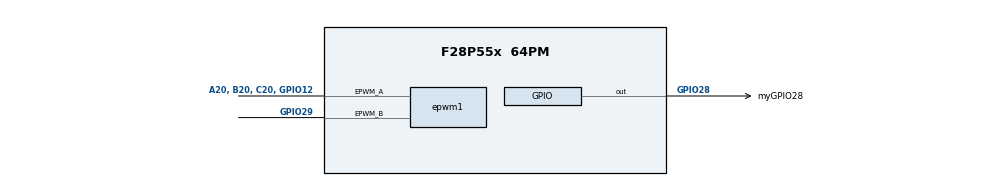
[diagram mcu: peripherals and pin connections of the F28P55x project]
/**
 * @cliArgs --device "F28P55x" --part "F28P55x_64PM" --package "64PM" --context "system" --product "C2000WARE@5.05.00.00"
 * @versions {"tool":"1.25.0+4268"}
 */

/**
 * Import the modules used in this configuration.
 */
const adc              = scripting.addModule("/driverlib/adc.js", {}, false);
const adc1             = adc.addInstance();
const adc2             = adc.addInstance();
const analog           = scripting.addModule("/driverlib/analog.js", {}, false);
const analog1          = analog.addInstance();
const asysctl          = scripting.addModule("/driverlib/asysctl.js");
const cputimer         = scripting.addModule("/driverlib/cputimer.js", {}, false);
const cputimer1        = cputimer.addInstance();
const dac              = scripting.addModule("/driverlib/dac.js", {}, false);
const dac1             = dac.addInstance();
const dma              = scripting.addModule("/driverlib/dma.js", {}, false);
const dma1             = dma.addInstance();
const epwm             = scripting.addModule("/driverlib/epwm.js", {}, false);
const epwm1            = epwm.addInstance();
const gpio             = scripting.addModule("/driverlib/gpio.js", {}, false);
const gpio1            = gpio.addInstance();
const inputxbar_input  = scripting.addModule("/driverlib/inputxbar_input.js", {}, false);
const inputxbar_input1 = inputxbar_input.addInstance();
const FFT              = scripting.addModule("/libraries/dsp/FPU/FFT/FFT.js", {}, false);
const FFT1             = FFT.addInstance();
const FPUfastRTS       = scripting.addModule("/libraries/math/FPUfastRTS/FPUfastRTS.js", {}, false);
const FPUfastRTS1      = FPUfastRTS.addInstance();

/**
 * Write custom configuration values to the imported modules.
 */
adc1.$name                    = "myADC0";
adc1.adcClockPrescaler        = "ADC_CLK_DIV_2_0";
adc1.interruptPulseMode       = "ADC_PULSE_END_OF_CONV";
adc1.enabledInts              = ["ADC_INT_NUMBER1"];
adc1.enableInterrupt1         = true;
adc1.registerInterrupts       = ["1"];
adc1.soc0Channel              = "ADC_CH_ADCIN6";
adc1.soc0Trigger              = "ADC_TRIGGER_EPWM7_SOCA";
adc1.enabledSOCs              = ["ADC_SOC_NUMBER0","ADC_SOC_NUMBER1","ADC_SOC_NUMBER10","ADC_SOC_NUMBER11","ADC_SOC_NUMBER12","ADC_SOC_NUMBER13","ADC_SOC_NUMBER14","ADC_SOC_NUMBER2","ADC_SOC_NUMBER3","ADC_SOC_NUMBER4","ADC_SOC_NUMBER5","ADC_SOC_NUMBER6","ADC_SOC_NUMBER7","ADC_SOC_NUMBER8","ADC_SOC_NUMBER9"];
adc1.soc0SampleWindow         = 20;
adc1.soc1Channel              = "ADC_CH_ADCIN2";
adc1.soc1Trigger              = "ADC_TRIGGER_EPWM7_SOCA";
adc1.soc1SampleWindow         = 20;
adc1.soc2Channel              = "ADC_CH_ADCIN11";
adc1.soc2Trigger              = "ADC_TRIGGER_EPWM7_SOCA";
adc1.soc2SampleWindow         = 20;
adc1.soc3Channel              = "ADC_CH_ADCIN12";
adc1.soc3Trigger              = "ADC_TRIGGER_EPWM7_SOCA";
adc1.soc3SampleWindow         = 20;
adc1.soc4Channel              = "ADC_CH_ADCIN4";
adc1.soc4Trigger              = "ADC_TRIGGER_EPWM7_SOCA";
adc1.soc4SampleWindow         = 20;
adc1.soc5Channel              = "ADC_CH_ADCIN15";
adc1.soc5Trigger              = "ADC_TRIGGER_EPWM7_SOCA";
adc1.soc5SampleWindow         = 20;
adc1.soc6Channel              = "ADC_CH_ADCIN5";
adc1.soc6Trigger              = "ADC_TRIGGER_EPWM7_SOCA";
adc1.soc6SampleWindow         = 20;
adc1.soc7Channel              = "ADC_CH_ADCIN7";
adc1.soc7Trigger              = "ADC_TRIGGER_EPWM7_SOCA";
adc1.soc7SampleWindow         = 20;
adc1.soc8Channel              = "ADC_CH_ADCIN9";
adc1.soc8Trigger              = "ADC_TRIGGER_EPWM7_SOCA";
adc1.soc8SampleWindow         = 20;
adc1.soc9Channel              = "ADC_CH_ADCIN3";
adc1.soc9Trigger              = "ADC_TRIGGER_EPWM7_SOCA";
adc1.soc9SampleWindow         = 20;
adc1.soc10Channel             = "ADC_CH_ADCIN14";
adc1.soc10Trigger             = "ADC_TRIGGER_EPWM7_SOCA";
adc1.soc10SampleWindow        = 20;
adc1.soc11Channel             = "ADC_CH_ADCIN1";
adc1.soc11Trigger             = "ADC_TRIGGER_EPWM7_SOCA";
adc1.soc11SampleWindow        = 20;
adc1.soc12Channel             = "ADC_CH_ADCIN8";
adc1.soc12Trigger             = "ADC_TRIGGER_EPWM7_SOCA";
adc1.soc12SampleWindow        = 20;
adc1.soc13Channel             = "ADC_CH_ADCIN24";
adc1.soc13Trigger             = "ADC_TRIGGER_EPWM7_SOCA";
adc1.soc13SampleWindow        = 20;
adc1.soc14Channel             = "ADC_CH_ADCIN25";
adc1.soc14Trigger             = "ADC_TRIGGER_EPWM7_SOCA";
adc1.soc14SampleWindow        = 20;
adc1.adcInt1.enableInterrupt  = true;
adc1.adcInt1.interruptHandler = "adcA1ISR";

adc2.$name             = "myADC1";
adc2.adcBase           = "ADCE_BASE";
adc2.adcClockPrescaler = "ADC_CLK_DIV_2_0";
adc2.enabledSOCs       = ["ADC_SOC_NUMBER0","ADC_SOC_NUMBER1","ADC_SOC_NUMBER2"];
adc2.soc0Channel       = "ADC_CH_ADCIN1";
adc2.soc0Trigger       = "ADC_TRIGGER_EPWM7_SOCA";
adc2.soc0SampleWindow  = 20;
adc2.soc1Channel       = "ADC_CH_ADCIN12";
adc2.soc1Trigger       = "ADC_TRIGGER_EPWM7_SOCA";
adc2.soc1SampleWindow  = 20;
adc2.soc2Channel       = "ADC_CH_ADCIN2";
adc2.soc2Trigger       = "ADC_TRIGGER_EPWM7_SOCA";
adc2.soc2SampleWindow  = 20;

asysctl.analogReference        = "INTERNAL";
asysctl.analogReferenceVoltage = "1P65";

cputimer1.$name                     = "myCPUTIMER0";
cputimer1.timerPeriod               = 23437;
cputimer1.enableInterrupt           = true;
cputimer1.registerInterrupts        = true;
cputimer1.startTimer                = true;
cputimer1.timerInt.interruptHandler = "cpuTimer0ISR";
cputimer1.timerInt.enableInterrupt  = true;

dac1.$name        = "myDAC0";
dac1.gainMode     = "DAC_GAIN_TWO";
dac1.shadowValue  = 2048;
dac1.enableOutput = true;

analog1.$name            = "myANALOGPinMux0";
adc1.analog              = analog1;
analog1.useCase          = "CUSTOM";
dac1.analog              = analog1;
analog1.useInterfacePins = ["A0, B15, C15, DACA_OUT","A1, B7, D11, CMP1_DACL","A11, B10, C0, PGA2_OUT","A12, C1, E11, PGA3_INP","A14, B14, C4, PGA1_OUT","A15, B9, C7, PGA1_INM","A2, B6, C9, PGA1_INP, GPIO224","A24, D0, E0, GPIO11","A25, D3, E3, GPIO17","A3, B3, PGA2_INP, C5, GPIO242","A4, B8, C14","A5, B12, C2, PGA2_INM","A6, D14, E14, GPIO228","A7, B30, C3, D12, E30, PGA3_INM","A8, B0, C11, PGA3_OUT","A9, B4, C8, GPIO227, GPIO236","B2, C6, E12, GPIO226","B24, D1, E1, GPIO33","C24, D2, E2, GPIO16"];
adc2.analog              = analog1;

dma1.$name            = "myDMA0";
dma1.enableTriggers   = true;
dma1.triggerSource    = "DMA_TRIGGER_ADCA1";
dma1.transferSize     = 1028;
dma1.emulationMode    = "DMA_EMULATION_FREE_RUN";
dma1.srcAddressManual = 0xB00;
dma1.destBurstStep    = 1;
dma1.destTransferStep = 1;

epwm1.epwmTimebase_hsClockDiv                                  = "EPWM_HSCLOCK_DIVIDER_1";
epwm1.epwmTimebase_period                                      = 23438;
epwm1.epwmCounterCompare_cmpA                                  = 11719;
epwm1.epwmActionQualifier_EPWM_AQ_OUTPUT_A_ON_TIMEBASE_ZERO    = "EPWM_AQ_OUTPUT_HIGH";
epwm1.epwmActionQualifier_EPWM_AQ_OUTPUT_A_ON_TIMEBASE_UP_CMPA = "EPWM_AQ_OUTPUT_LOW";
epwm1.epwmActionQualifier_EPWM_AQ_OUTPUT_B_ON_TIMEBASE_ZERO    = "EPWM_AQ_OUTPUT_HIGH";
epwm1.epwmActionQualifier_EPWM_AQ_OUTPUT_B_ON_TIMEBASE_UP_CMPA = "EPWM_AQ_OUTPUT_LOW";
epwm1.epwmEventTrigger_EPWM_SOC_A_triggerEnable                = true;
epwm1.epwmEventTrigger_EPWM_SOC_A_triggerSource                = "EPWM_SOC_TBCTR_ZERO";
epwm1.epwmEventTrigger_EPWM_SOC_A_triggerEventPrescalar        = "1";
epwm1.$name                                                    = "myEPWM7";
epwm1.epwmTimebase_syncInPulseSource                           = "EPWM_SYNC_IN_PULSE_SRC_INPUTXBAR_OUT5";
epwm1.epwmTimebase_phaseEnable                                 = true;
epwm1.epwmTripZone_tzInterruptSource                           = ["EPWM_TZ_INTERRUPT_OST"];
epwm1.epwmTripZone_EPWM_TZ_ACTION_EVENT_TZA                    = "EPWM_TZ_ACTION_LOW";
epwm1.epwmTripZone_EPWM_TZ_ACTION_EVENT_TZB                    = "EPWM_TZ_ACTION_HIGH";
epwm1.epwmTimebase_phaseShift                                  = 300;
epwm1.epwm.$assign                                             = "EPWM7";
epwm1.epwm.epwm_aPin.$assign                                   = "A20, B20, C20, GPIO12";
epwm1.epwm.epwm_bPin.$assign                                   = "GPIO29";

gpio1.$name                      = "myGPIO28";
gpio1.useInterrupt               = true;
gpio1.gpioPin.$assign            = "GPIO28";
gpio1.xint.xintNum               = "GPIO_INT_XINT2";
gpio1.xint.registerInterrupts    = true;
gpio1.xint.enableInt             = true;
gpio1.xint.xInt.interruptHandler = "GPIOISR";
gpio1.xint.xInt.enableInterrupt  = true;

inputxbar_input1.$name         = "myINPUTXBARINPUT0";
inputxbar_input1.inputxbarGpio = "GPIO28";
gpio1.xint.inputxbar           = inputxbar_input1;

FFT1.$name                  = "myFFT0";
FFT1.RFFT.create(1);
FFT1.RFFT[0].$name          = "myRFFT0";
FFT1.RFFT[0].inPtr          = "inPtr";
FFT1.RFFT[0].outPtr         = "outPtr";
FFT1.RFFT[0].magPtr         = "magPtr";
FFT1.RFFT[0].phasPtr        = "phPtr";
FFT1.RFFT[0].numStages      = 8;
FFT1.RFFT[0].sincosFunction = false;
FFT1.RFFT[0].coeffPtr       = "twiddlePtr";

FPUfastRTS1.$name = "myFFR0";

/**
 * Pinmux solution for unlocked pins/peripherals. This ensures that minor changes to the automatic solver in a future
 * version of the tool will not impact the pinmux you originally saw.  These lines can be completely deleted in order to
 * re-solve from scratch.
 */
analog1.analog.$suggestSolution                                       = "ANALOG";
analog1.analog["a0, b15, c15, daca_outPin"].$suggestSolution          = "A0, B15, C15, DACA_OUT";
analog1.analog["a2, b6, c9, pga1_inp, gpio224Pin"].$suggestSolution   = "A2, B6, C9, PGA1_INP, GPIO224";
analog1.analog["a3, b3, pga2_inp, c5, gpio242Pin"].$suggestSolution   = "A3, B3, PGA2_INP, C5, GPIO242";
analog1.analog["a4, b8, c14Pin"].$suggestSolution                     = "A4, B8, C14";
analog1.analog["a5, b12, c2, pga2_inmPin"].$suggestSolution           = "A5, B12, C2, PGA2_INM";
analog1.analog["a6, d14, e14, gpio228Pin"].$suggestSolution           = "A6, D14, E14, GPIO228";
analog1.analog["a7, b30, c3, d12, e30, pga3_inmPin"].$suggestSolution = "A7, B30, C3, D12, E30, PGA3_INM";
analog1.analog["a8, b0, c11, pga3_outPin"].$suggestSolution           = "A8, B0, C11, PGA3_OUT";
analog1.analog["a9, b4, c8, gpio227, gpio236Pin"].$suggestSolution    = "A9, B4, C8, GPIO227, GPIO236";
analog1.analog["a11, b10, c0, pga2_outPin"].$suggestSolution          = "A11, B10, C0, PGA2_OUT";
analog1.analog["a12, c1, e11, pga3_inpPin"].$suggestSolution          = "A12, C1, E11, PGA3_INP";
analog1.analog["a14, b14, c4, pga1_outPin"].$suggestSolution          = "A14, B14, C4, PGA1_OUT";
analog1.analog["a15, b9, c7, pga1_inmPin"].$suggestSolution           = "A15, B9, C7, PGA1_INM";
analog1.analog["a24, d0, e0, gpio11Pin"].$suggestSolution             = "A24, D0, E0, GPIO11";
analog1.analog["a25, d3, e3, gpio17Pin"].$suggestSolution             = "A25, D3, E3, GPIO17";
analog1.analog["b2, c6, e12, gpio226Pin"].$suggestSolution            = "B2, C6, E12, GPIO226";
analog1.analog["b24, d1, e1, gpio33Pin"].$suggestSolution             = "B24, D1, E1, GPIO33";
analog1.analog["c24, d2, e2, gpio16Pin"].$suggestSolution             = "C24, D2, E2, GPIO16";
analog1.analog["a1, b7, d11, cmp1_daclPin"].$suggestSolution          = "A1, B7, D11, CMP1_DACL";
gpio1.gpioPin["GPIO#"].$suggestSolution                               = "A16, B16, C16, GPIO28";
